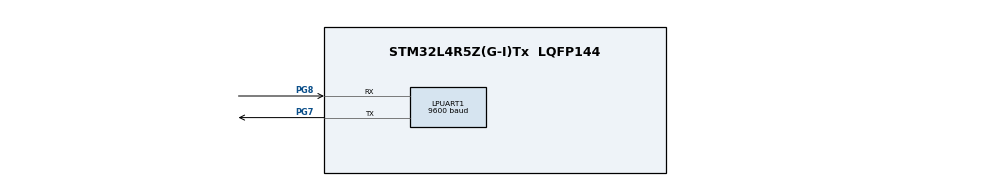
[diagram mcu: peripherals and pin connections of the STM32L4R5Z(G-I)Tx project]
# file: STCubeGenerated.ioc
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LPUART1.BaudRate=9600
LPUART1.WordLength=UART_WORDLENGTH_8B
Mcu.Family=STM32L4
Mcu.Name=STM32L4R5Z(G-I)Tx
Mcu.Package=LQFP144
NVIC.PriorityGroup=NVIC_PRIORITYGROUP_4
PG7.GPIO_Speed=GPIO_SPEED_FREQ_LOW
PG7.Mode=Asynchronous
PG7.Signal=LPUART1_TX
PG8.GPIO_Speed=GPIO_SPEED_FREQ_LOW
PG8.Mode=Asynchronous
PG8.Signal=LPUART1_RX
ProjectManager.HeapSize=0x200
ProjectManager.StackSize=0x400
ProjectManager.TargetToolchain=MDK-ARM V5
RCC.HSE_VALUE=8000000
RCC.HSI48_VALUE=48000000
RCC.HSI_VALUE=16000000
RCC.LSE_VALUE=32768
RCC.MSI_VALUE=4000000
RCC.VCOOutputFreq_Value=32000000
board=custom

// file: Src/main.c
/* USER CODE BEGIN Header */
/**
  ******************************************************************************
  * @file           : main.c
  * @brief          : Main program body
  ******************************************************************************
  * @attention
  *
  * <h2><center>&copy; Copyright (c) 2020 STMicroelectronics.
  * All rights reserved.</center></h2>
  *
  * This software component is licensed by ST under BSD 3-Clause license,
  * the "License"; You may not use this file except in compliance with the
  * License. You may obtain a copy of the License at:
  *                        opensource.org/licenses/BSD-3-Clause
  *
  ******************************************************************************
  */
/* USER CODE END Header */

#include "main.h"

/* USER CODE BEGIN Includes */
#include <stdio.h>
#include <..\..\..\..\..\switch_source.h>
/* USER CODE END Includes */

UART_HandleTypeDef hlpuart1;
UART_HandleTypeDef huart1;

void SystemClock_Config(void);
static void MX_GPIO_Init(void);
static void MX_LPUART1_UART_Init(void);
/* USER CODE BEGIN PFP */
extern void MEASUREMENT_INIT(void);
extern uint32_t MEASUREMENT(void);
extern uint32_t CONVERT_MEASUREMENT(int);
/* USER CODE END PFP */

/* USER CODE BEGIN 0 */
uint8_t Header[31]={"Distance Measurement Program\n\r"};
uint8_t Switch_Response[9]={"Hello!\n\r"};
/* USER CODE END 0 */

int main(void)
{
  /* USER CODE BEGIN 1 */
   char print_buf[50];
	 uint16_t feet, frac, inches;
	 uint8_t input;
	 uint32_t meas_output = 0;
  /* USER CODE END 1 */

  /* MCU Configuration--------------------------------------------------------*/

  /* Reset of all peripherals, Initializes the Flash interface and the Systick. */
  HAL_Init();

  /* Configure the system clock */
  SystemClock_Config();

  /* Initialize all configured peripherals */
  MX_GPIO_Init();
  MX_LPUART1_UART_Init();

	/* USER CODE BEGIN Init */
  SWITCH_INIT();
  MEASUREMENT_INIT();
	/* USER CODE END Init */

  /* USER CODE BEGIN 2 */
  HAL_UART_Transmit(&hlpuart1, Header, 30, 100);
  /* USER CODE END 2 */

  /* Infinite loop */
  while (1)
  {
    input=SWITCH_READ();
		if(input==1)
		{
			   HAL_UART_Transmit(&hlpuart1, Switch_Response, 8, 100); /*** This can be removed ***/
			   meas_output=MEASUREMENT();
		}
    /* USER CODE BEGIN 3 */
    if(meas_output != 0xFFFFFFFF)
    {
      meas_output = CONVERT_MEASUREMENT(meas_output);

      /* STEP #9: print distance measurement in feet */
      feet = meas_output >> 8;
      inches = ( (meas_output & 0xFF) * 100 ) / 256;
      sprintf(print_buf, "%u.%2.2u feet\n", feet, inches);
    }
    else
    {
       sprintf(print_buf, "%s\n", "ERROR: no echo detected");
    }
  }
  /* USER CODE END 3 */
}

void SystemClock_Config(void)
{
  RCC_OscInitTypeDef RCC_OscInitStruct = {0};
  RCC_ClkInitTypeDef RCC_ClkInitStruct = {0};
  RCC_PeriphCLKInitTypeDef PeriphClkInit = {0};

  /** Configure the main internal regulator output voltage
  */
  if (HAL_PWREx_ControlVoltageScaling(PWR_REGULATOR_VOLTAGE_SCALE1) != HAL_OK)
  {
    Error_Handler();
  }
  /** Initializes the CPU, AHB and APB busses clocks
  */
  RCC_OscInitStruct.OscillatorType = RCC_OSCILLATORTYPE_MSI;
  RCC_OscInitStruct.MSIState = RCC_MSI_ON;
  RCC_OscInitStruct.MSICalibrationValue = 0;
  RCC_OscInitStruct.MSIClockRange = RCC_MSIRANGE_6;
  RCC_OscInitStruct.PLL.PLLState = RCC_PLL_NONE;
  if (HAL_RCC_OscConfig(&RCC_OscInitStruct) != HAL_OK)
  {
    Error_Handler();
  }
  /** Initializes the CPU, AHB and APB busses clocks
  */
  RCC_ClkInitStruct.ClockType = RCC_CLOCKTYPE_HCLK|RCC_CLOCKTYPE_SYSCLK
                              |RCC_CLOCKTYPE_PCLK1|RCC_CLOCKTYPE_PCLK2;
  RCC_ClkInitStruct.SYSCLKSource = RCC_SYSCLKSOURCE_MSI;
  RCC_ClkInitStruct.AHBCLKDivider = RCC_SYSCLK_DIV1;
  RCC_ClkInitStruct.APB1CLKDivider = RCC_HCLK_DIV1;
  RCC_ClkInitStruct.APB2CLKDivider = RCC_HCLK_DIV1;

  if (HAL_RCC_ClockConfig(&RCC_ClkInitStruct, FLASH_LATENCY_0) != HAL_OK)
  {
    Error_Handler();
  }
  PeriphClkInit.PeriphClockSelection = RCC_PERIPHCLK_LPUART1;
  PeriphClkInit.Lpuart1ClockSelection = RCC_LPUART1CLKSOURCE_PCLK1;
  if (HAL_RCCEx_PeriphCLKConfig(&PeriphClkInit) != HAL_OK)
  {
    Error_Handler();
  }
}

static void MX_LPUART1_UART_Init(void)
{

  hlpuart1.Instance = LPUART1;
  hlpuart1.Init.BaudRate = 9600;
  hlpuart1.Init.WordLength = UART_WORDLENGTH_8B;
  hlpuart1.Init.StopBits = UART_STOPBITS_1;
  hlpuart1.Init.Parity = UART_PARITY_NONE;
  hlpuart1.Init.Mode = UART_MODE_TX_RX;
  hlpuart1.Init.HwFlowCtl = UART_HWCONTROL_NONE;
  hlpuart1.Init.OneBitSampling = UART_ONE_BIT_SAMPLE_DISABLE;
  hlpuart1.Init.ClockPrescaler = UART_PRESCALER_DIV1;
  hlpuart1.AdvancedInit.AdvFeatureInit = UART_ADVFEATURE_NO_INIT;
  hlpuart1.FifoMode = UART_FIFOMODE_DISABLE;
  if (HAL_UART_Init(&hlpuart1) != HAL_OK)
  {
    Error_Handler();
  }
  if (HAL_UARTEx_SetTxFifoThreshold(&hlpuart1, UART_TXFIFO_THRESHOLD_1_8) != HAL_OK)
  {
    Error_Handler();
  }
  if (HAL_UARTEx_SetRxFifoThreshold(&hlpuart1, UART_RXFIFO_THRESHOLD_1_8) != HAL_OK)
  {
    Error_Handler();
  }
  if (HAL_UARTEx_DisableFifoMode(&huart1) != HAL_OK)
  {
    Error_Handler();
  }

}

static void MX_GPIO_Init(void)
{

  /* GPIO Ports Clock Enable */
  __HAL_RCC_GPIOG_CLK_ENABLE();
  HAL_PWREx_EnableVddIO2();

}

void Error_Handler(void)
{
}

/************************ (C) COPYRIGHT STMicroelectronics *****END OF FILE****/
